# PIC32MK0512GPD100 device description
Architecture: MIPS; Family: PIC32MK; Series: PIC32MK
Registers are 32-bit, read-write, no defined reset value unless marked. A register's access mark holds for its fields unless they carry their own. Offsets are from the block's base; [hi:lo] are bit positions; {n}, {i} and the like mark numbered series; 'fields as' and 'values as' point back to an identical list.

## PCACHE
Instances: PCACHE 0x1f800800 in periph_pb1_std
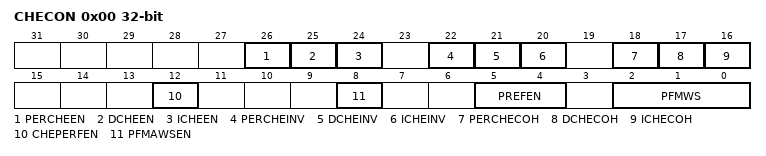
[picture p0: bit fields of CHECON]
0x00 CHECON — Cache Module Control Register
  [26] PERCHEEN — Peripheral Cache Enable bit
    1=Peripheral cache is enabled; 0=Peripheral cache is disabled
  [25] DCHEEN — Data Cache Enable bit
    1=Data cache is enabled; 0=Data cache is disabled
  [24] ICHEEN — Instruction Cache Enable bit
    1=Instruction cache is enabled; 0=Instruction cache is disabled
  [22] PERCHEINV — Peripheral Cache Invalidate bit
    1=Force invalidate cache/invalidate busy; 0=Cache Invalidation follows CHECOH/invalid complete
  [21] DCHEINV — Data Cache Invalidate bit
    values as PERCHEINV
  [20] ICHEINV — Instruction Cache Invalidate bit
    values as PERCHEINV
  [18] PERCHECOH — Peripheral Auto-cache Coherency Control bit
    1=Automatically invalidate cache on a programming event; 0=Do not automatically invalidate cache on a programming event
  [17] DCHECOH — Data Auto-cache Coherency Control bit
    values as PERCHECOH
  [16] ICHECOH — Instruction Auto-cache Coherency Control bit
    values as PERCHECOH
  [12] CHEPERFEN — Cache Performance Counters Enable bit
    1=Performance counters are enabled; 0=Performance counters are disabled
  [8] PFMAWSEN — PFM Address Wait State Enable bit
    1=Add one more Wait State to flash address setup (suggested for higher system clock frequencies); 0=Add no Wait States to the flash address setup (suggested for lower system clock frequencies to achieve higher performance)
  [5:4] PREFEN — Predictive Prefetch Enable bits
    3=Disable predictive prefetch; 2=Disable predictive prefetch; 1=Enable predictive prefetch for CPU instructions only; 0=Disable predictive prefetch
  [2:0] PFMWS — PFM Access Time Defined in Terms of SYSCLK Wait States bits
    7=Seven Wait states; 2=Two Wait states; 1=One Wait state; 0=Zero Wait states
0x20 CHEHIT ro — CACHE Hit Status Register
0x30 CHEMIS ro — CACHE Miss Status Register

## RPIN
Instances: RPIN 0x1f801404 in periph_pb1_std
0x00 INT1R
  [3:0] INT1R
0x04 INT2R
  [3:0] INT2R
0x08 INT3R
  [3:0] INT3R
0x0C INT4R
  [3:0] INT4R
{0xC+4i} T{i}CKR (i=2..9)
  [3:0] T{i}CKR
{0x30+4i} IC{i}R (i=1..9)
  [3:0] IC{i}R
0x58 OCFAR
  [3:0] OCFAR
0x5C OCFBR
  [3:0] OCFBR
{0x58+8i} U{i}RXR (i=1..6)
  [3:0] U{i}RXR
{0x5C+8i} U{i}CTSR (i=1..6)
  [3:0] U{i}CTSR
{0x88+0xC*i} SDI{i}R (i=1..4)
  [3:0] SDI{i}R
{0x8C+0xC*i} SS{i}R (i=1..4)
  [3:0] SS{i}R
0xA8 SCK3R
  [3:0] SCK3R
0xB4 SCK4R
  [3:0] SCK4R
0xC0 C1RXR
  [3:0] C1RXR
0xC4 C2RXR
  [3:0] C2RXR
0xC8 REFIR
  [3:0] REFIR
{0xCC+4i} IC{i}R (i=10..16)
  [3:0] IC{i}R
0x110 SCK5R
  [3:0] SCK5R
0x114 SDI5R
  [3:0] SDI5R
0x118 SS5R
  [3:0] SS5R
0x11C SCK6R
  [3:0] SCK6R
0x120 SDI6R
  [3:0] SDI6R
0x124 SS6R
  [3:0] SS6R
0x128 C3RXR
  [3:0] C3RXR
0x12C C4RXR
  [3:0] C4RXR

## RPOR
Instances: RPOR 0x1f801600 in periph_pb1_std
{0x0+4i} RPA{i}R (i=0..4)
  [4:0] RPA{i}R
0x1C RPA7R
  [4:0] RPA7R
0x20 RPA8R
  [4:0] RPA8R
0x2C RPA11R
  [4:0] RPA11R
0x30 RPA12R
  [4:0] RPA12R
0x38 RPA14R
  [4:0] RPA14R
0x3C RPA15R
  [4:0] RPA15R
{0x40+4i} RPB{i}R (i=0..7)
  [4:0] RPB{i}R
{0x40+4i} RPB{i}R (i=9..15)
  [4:0] RPB{i}R
{0x80+4i} RPC{i}R (i=0..2)
  [4:0] RPC{i}R
0x90 RPC4R
  [4:0] RPC4R
{0x80+4i} RPC{i}R (i=6..10)
  [4:0] RPC{i}R
0xB0 RPC12R
  [4:0] RPC12R
0xBC RPC15R
  [4:0] RPC15R
{0xC0+4i} RPD{i}R (i=3..6)
  [4:0] RPD{i}R
0x100 RPE0R
  [4:0] RPE0R
0x104 RPE1R
  [4:0] RPE1R
0x138 RPE14R
  [4:0] RPE14R
0x13C RPE15R
  [4:0] RPE15R
0x140 RPF0R
  [4:0] RPF0R
0x144 RPF1R
  [4:0] RPF1R
0x180 RPG0R
  [4:0] RPG0R
0x184 RPG1R
  [4:0] RPG1R
{0x180+4i} RPG{i}R (i=6..9)
  [4:0] RPG{i}R
0x1B0 RPG12R
  [4:0] RPG12R

## RTCC
Instances: RTCC 0x1f8c0000 in periph_pb6_std
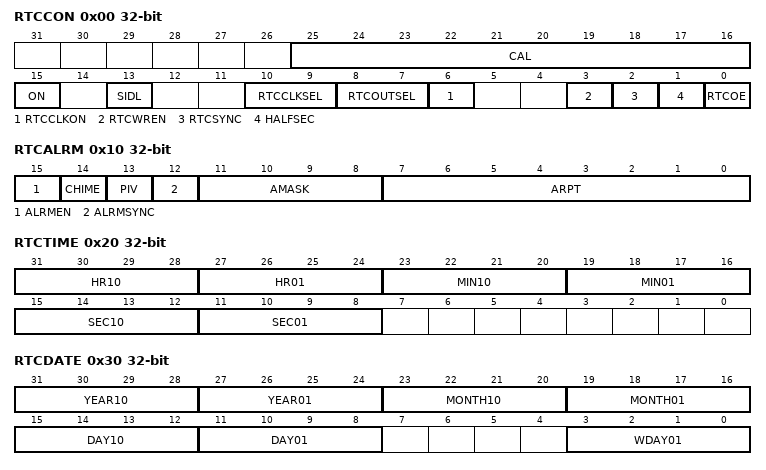
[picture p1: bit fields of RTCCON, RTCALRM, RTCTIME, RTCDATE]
0x00 RTCCON — Real-Time Clock and Calendar Control Register
  [25:16] CAL — Real-Time Clock Drift Calibration bits
    0x1ff=Maximum positive adjustment; 1=Minimum positive adjustment; 0=No adjustment; 0x3ff=Minimum negative adjustment; 0x200=Minimum negative adjustment
  [15] ON — RTCC On bit
    1=RTCC module is enabled; 0=RTCC module is disabled
  [13] SIDL — Stop in Idle Mode bit
    1=Disables RTCC operation when CPU enters Idle mode; 0=Continue normal operation when CPU enters Idle mode
  [10:9] RTCCLKSEL — RTCC Clock Select bits
    1=RTCC uses the external 32.768 kHz Secondary Oscillator (SOSC); 0=RTCC uses the internal 32 kHz oscillator (LPRC)
  [8:7] RTCOUTSEL — RTCC Output Data Select bits
    2=RTCC Clock is presented on the RTCC pin; 1=Seconds Clock is presented on the RTCC pin; 0=Alarm Pulse is presented on the RTCC pin when the alarm interrupt is triggered
  [6] RTCCLKON — RTCC Clock Enable Status bit
    1=RTCC Clock is actively running; 0=RTCC Clock is not running
  [3] RTCWREN — Real-Time Clock Value Registers Write Enable bit
    1=Real-Time Clock Value registers can be written to by the user; 0=Real-Time Clock Value registers are locked out from being written to by the user
  [2] RTCSYNC — Real-Time Clock Value Registers Read Synchronization bit
    1=Real-time clock value registers can change while reading (due to a rollover ripple that results in an invalid data read). If the register is read twice and results in the same data; 0=Real-time clock value registers can be read without concern about a rollover ripple
  [1] HALFSEC — Half-Second Status bit
    1=Second half period of a second; 0=First half period of a second
  [0] RTCOE — RTCC Output Enable bit
    1=RTCC output is enabled; 0=RTCC output is not enabled
0x10 RTCALRM — Real-Time Clock ALARM Control Register
  [15] ALRMEN — Alarm Enable bit
    1=Alarm is enabled; 0=Alarm is disabled
  [14] CHIME — Chime Enable bit
    1=Chime is enabled ARPT is allowed to rollover from 0x00 to 0xFF; 0=Chime is disabled ARPT stops once it reaches 0x00
  [13] PIV — Alarm Pulse Initial Value bit
    0=low initial value of the Alarm Pulse (When ALRMEN = 0); 1=high initial value of the Alarm Pulse (When ALRMEN = 0)
  [12] ALRMSYNC — Alarm Sync bit
    1=ARPT and ALRMEN may change as a result of a half second rollover during a read. The ARPT must be read repeatedly until the same value is read twice. This must be done since multiple bits may be changing.; 0=ARPT and ALRMEN can be read without concerns of rollover because the prescaler is more than 32 real-time clocks away from a half-second rollover
  [11:8] AMASK — Alarm Mask Configuration bits
    0=Every half-second; 1=Every second; 2=Every 10 seconds; 3=Every minute; 4=Every 10 minutes; 5=Every hour; 6=Once a day; 7=Once a week; 8=Once a month; 9=Once a year (except when configured for February 29
  [7:0] ARPT — Alarm Repeat Counter Value bits
    255=Alarm will trigger 256 times; 254=Alarm will trigger 255 times; 1=Alarm will trigger two times; 0=Alarm will trigger one time
0x20 RTCTIME — Real-Time Clock Time Value Register
  [31:28] HR10, [27:24] HR01, [23:20] MIN10, [19:16] MIN01, [15:12] SEC10, [11:8] SEC01
0x30 RTCDATE — Real-Time Clock Date Value Register
  [31:28] YEAR10, [27:24] YEAR01, [23:20] MONTH10, [19:16] MONTH01, [15:12] DAY10, [11:8] DAY01, [3:0] WDAY01
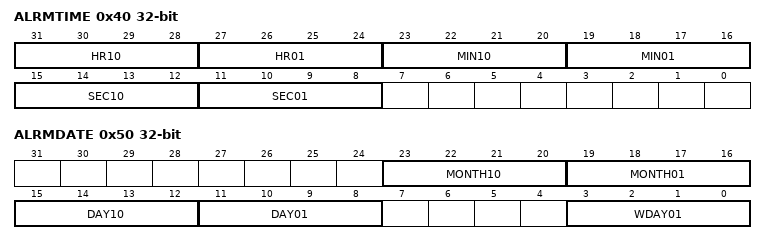
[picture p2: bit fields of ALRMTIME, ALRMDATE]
0x40 ALRMTIME — Alarm Time Value Register
  fields as RTCTIME
0x50 ALRMDATE — Alarm Date Value Register
  [23:20] MONTH10, [19:16] MONTH01, [15:12] DAY10, [11:8] DAY01, [3:0] WDAY01

## Notices in the file
Copyright (c) 2017 Microchip Technology Inc.
SPDX-License-Identifier: Apache-2.0
Licensed under the Apache License, Version 2.0 (the "License");
you may not use this file except in compliance with the License.
You may obtain a copy of the License at
http://www.apache.org/licenses/LICENSE-2.0
Unless required by applicable law or agreed to in writing, software
distributed under the License is distributed on an "AS IS" BASIS,
WITHOUT WARRANTIES OR CONDITIONS OF ANY KIND, either express or implied.
See the License for the specific language governing permissions and
limitations under the License.
